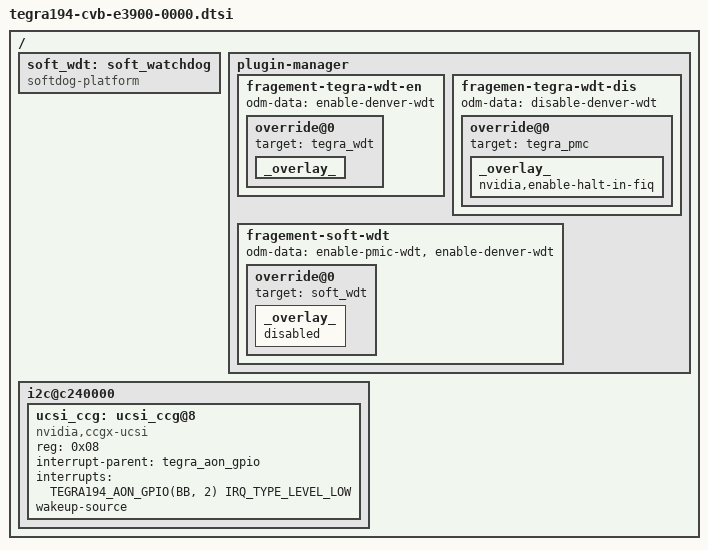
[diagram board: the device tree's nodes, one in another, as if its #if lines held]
/*
 * Copyright (c) 2019-2020, NVIDIA CORPORATION.  All rights reserved.
 *
 * This program is free software; you can redistribute it and/or modify it
 * under the terms and conditions of the GNU General Public License,
 * version 2, as published by the Free Software Foundation.
 *
 * This program is distributed in the hope it will be useful, but WITHOUT
 * ANY WARRANTY; without even the implied warranty of MERCHANTABILITY or
 * FITNESS FOR A PARTICULAR PURPOSE.  See the GNU General Public License for
 * more details.
 *
 * You should have received a copy of the GNU General Public License
 * along with this program.  If not, see <http://www.gnu.org/licenses/>.
 */

/ {
	soft_wdt:soft_watchdog {
		compatible = "softdog-platform";
		status = "okay";
	};

	plugin-manager {
		fragement-tegra-wdt-en {
			odm-data = "enable-denver-wdt";
			override@0 {
				target = <&tegra_wdt>;
				_overlay_ {
					status = "okay";
				};
			};
		};

		fragemen-tegra-wdt-dis {
			odm-data = "disable-denver-wdt";
			override@0 {
				target = <&tegra_pmc>;
				_overlay_ {
					nvidia,enable-halt-in-fiq;
				};
			};
		};

		fragement-soft-wdt {
			odm-data = "enable-pmic-wdt",
				   "enable-denver-wdt";
			override@0 {
				target = <&soft_wdt>;
				_overlay_ {
					status = "disabled";
				};
			};
		};
	};

	i2c@c240000 {
		ucsi_ccg: ucsi_ccg@8 {
#if TEGRA_XUSB_DT_VERSION >= DT_VERSION_3
			compatible = "nvidia,ccgx-ucsi";
#else
			compatible = "nvidia,ucsi_ccg";
			ccg,irqflags = <IRQF_TRIGGER_LOW>;
#endif
			reg = <0x08>;
			interrupt-parent = <&tegra_aon_gpio>;
			interrupts = <TEGRA194_AON_GPIO(BB, 2) IRQ_TYPE_LEVEL_LOW>;
			wakeup-source;
			status = "okay";
		};
	};
};
